AUTOSAR XML (schema 4.0)
package /ADAS_Architecture
  application sw component type SWC_CameraPerception
    provide port P_TrackedObjects: provided-interface=If_TrackedObjects
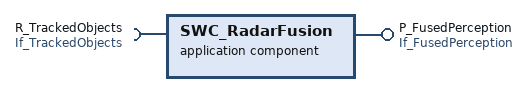
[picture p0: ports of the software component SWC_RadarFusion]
  application sw component type SWC_RadarFusion
    require port R_TrackedObjects: required-interface=If_TrackedObjects
    provide port P_FusedPerception: provided-interface=If_FusedPerception
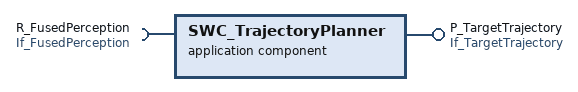
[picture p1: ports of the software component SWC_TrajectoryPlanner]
  application sw component type SWC_TrajectoryPlanner
    require port R_FusedPerception: required-interface=If_FusedPerception
    provide port P_TargetTrajectory: provided-interface=If_TargetTrajectory
